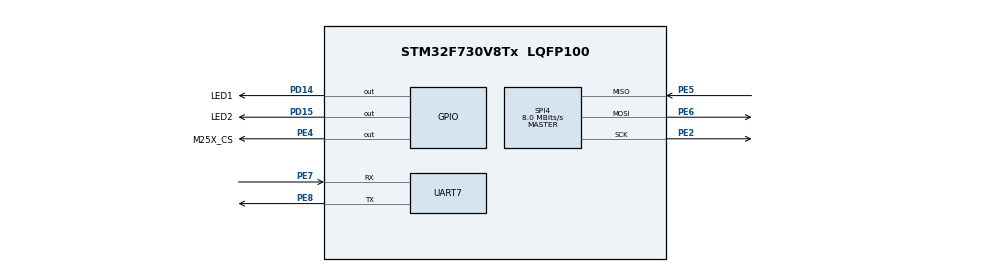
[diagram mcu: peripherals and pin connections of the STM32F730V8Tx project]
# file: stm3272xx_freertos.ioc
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Mcu.Family=STM32F7
PH0-OSC_IN.Signal=RCC_OSC_IN
SPI4.VirtualType=VM_MASTER
FREERTOS.Tasks01=defaultTask,24,128,StartDefaultTask,Default,NULL,Dynamic,NULL,NULL;sys_monitor,24,2048,thread_entry_sys_monitor,Default,NULL,Dynamic,NULL,NULL
PD15.GPIO_Label=LED2
SPI4.DataSize=SPI_DATASIZE_8BIT
SPI4.Direction=SPI_DIRECTION_2LINES
ProjectManager.StackSize=0x400
VP_FREERTOS_VS_CMSIS_V2.Mode=CMSIS_V2
PE8.Mode=Asynchronous
NVIC.SPI4_IRQn=true\:5\:0\:false\:false\:true\:true\:true\:true
SPI4.Mode=SPI_MODE_MASTER
ProjectManager.TargetToolchain=STM32CubeIDE
PE2.Mode=Full_Duplex_Master
PE5.Signal=SPI4_MISO
RCC.USBFreq_Value=96000000
SPI4.CLKPolarity=SPI_POLARITY_LOW
RCC.LSE_VALUE=32768
PH0-OSC_IN.Mode=HSE-External-Clock-Source
RCC.HSE_VALUE=25000000
PD14.PinState=GPIO_PIN_SET
board=custom
RCC.VCOOutputFreq_Value=192000000
PD15.PinState=GPIO_PIN_SET
PE6.Mode=Full_Duplex_Master
PE8.Signal=UART7_TX
PE5.Mode=Full_Duplex_Master
PE4.GPIO_Label=M25X_CS
PH1-OSC_OUT.Signal=RCC_OSC_OUT
PE2.Signal=SPI4_SCK
SPI4.CalculateBaudRate=8.0 MBits/s
PD14.GPIO_Label=LED1
PE6.Signal=SPI4_MOSI
PE4.Signal=GPIO_Output
Mcu.Name=STM32F730V8Tx
PD14.Signal=GPIO_Output
PH1-OSC_OUT.Mode=HSE-External-Clock-Source
Mcu.Package=LQFP100
PE7.Mode=Asynchronous
ProjectManager.HeapSize=0x200
RCC.HSI_VALUE=16000000
SPI4.CLKPhase=SPI_PHASE_1EDGE
NVIC.PriorityGroup=NVIC_PRIORITYGROUP_4
PE4.PinState=GPIO_PIN_SET
PE7.Signal=UART7_RX
PD15.Signal=GPIO_Output
NVIC.UART7_IRQn=true\:5\:0\:false\:false\:true\:true\:true\:true

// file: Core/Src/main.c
/* USER CODE BEGIN Header */
/**
  ******************************************************************************
  * @file           : main.c
  * @brief          : Main program body
  ******************************************************************************
  * @attention
  *
  * <h2><center>&copy; Copyright (c) 2023 STMicroelectronics.
  * All rights reserved.</center></h2>
  *
  * This software component is licensed by ST under BSD 3-Clause license,
  * the "License"; You may not use this file except in compliance with the
  * License. You may obtain a copy of the License at:
  *                        opensource.org/licenses/BSD-3-Clause
  *
  ******************************************************************************
  */
/* USER CODE END Header */
#include "main.h"
#include "cmsis_os.h"

/* USER CODE BEGIN Includes */
#include "app.h"
/* USER CODE END Includes */

SPI_HandleTypeDef hspi4;

UART_HandleTypeDef huart7;

/* Definitions for defaultTask */
osThreadId_t defaultTaskHandle;
const osThreadAttr_t defaultTask_attributes = {
  .name = "defaultTask",
  .stack_size = 128 * 4,
  .priority = (osPriority_t) osPriorityNormal,
};
/* Definitions for sys_monitor */
osThreadId_t sys_monitorHandle;
const osThreadAttr_t sys_monitor_attributes = {
  .name = "sys_monitor",
  .stack_size = 2048 * 4,
  .priority = (osPriority_t) osPriorityNormal,
};

void SystemClock_Config(void);
static void MX_GPIO_Init(void);
static void MX_SPI4_Init(void);
static void MX_UART7_Init(void);
void StartDefaultTask(void *argument);
void thread_entry_sys_monitor(void *argument);

/* USER CODE BEGIN 0 */
#ifdef __GNUC__
  #define PUTCHAR_PROTOTYPE int __io_putchar(int ch)
#else
  #define PUTCHAR_PROTOTYPE int fputc(int ch, FILE *f)
#endif
PUTCHAR_PROTOTYPE
{
    HAL_UART_Transmit(&huart7, (uint8_t *)&ch, 1, 0xFF);
    return ch;
}
/* USER CODE END 0 */

int main(void)
{

  /* MCU Configuration--------------------------------------------------------*/

  /* Reset of all peripherals, Initializes the Flash interface and the Systick. */
  HAL_Init();

  /* Configure the system clock */
  SystemClock_Config();

  /* Initialize all configured peripherals */
  MX_GPIO_Init();
  MX_SPI4_Init();
  MX_UART7_Init();
  /* USER CODE BEGIN 2 */
//   W25QXX_Erase_Chip();
  W25QXX_Init();
  printf("W25QXX Init:%04X\r\n", W25QXX_ReadID());
  /* USER CODE END 2 */

  /* Init scheduler */
  osKernelInitialize();

  /* Create the thread(s) */
  /* creation of defaultTask */
  defaultTaskHandle = osThreadNew(StartDefaultTask, NULL, &defaultTask_attributes);

  /* creation of sys_monitor */
  sys_monitorHandle = osThreadNew(thread_entry_sys_monitor, NULL, &sys_monitor_attributes);

  /* Start scheduler */
  osKernelStart();

  /* We should never get here as control is now taken by the scheduler */
  /* Infinite loop */
  while (1)
  {

  }
}

void SystemClock_Config(void)
{
  RCC_OscInitTypeDef RCC_OscInitStruct = {0};
  RCC_ClkInitTypeDef RCC_ClkInitStruct = {0};
  RCC_PeriphCLKInitTypeDef PeriphClkInitStruct = {0};

  /** Configure the main internal regulator output voltage
  */
  __HAL_RCC_PWR_CLK_ENABLE();
  __HAL_PWR_VOLTAGESCALING_CONFIG(PWR_REGULATOR_VOLTAGE_SCALE3);
  /** Initializes the RCC Oscillators according to the specified parameters
  * in the RCC_OscInitTypeDef structure.
  */
  RCC_OscInitStruct.OscillatorType = RCC_OSCILLATORTYPE_HSI;
  RCC_OscInitStruct.HSIState = RCC_HSI_ON;
  RCC_OscInitStruct.HSICalibrationValue = RCC_HSICALIBRATION_DEFAULT;
  RCC_OscInitStruct.PLL.PLLState = RCC_PLL_NONE;
  if (HAL_RCC_OscConfig(&RCC_OscInitStruct) != HAL_OK)
  {
    Error_Handler();
  }
  /** Initializes the CPU, AHB and APB buses clocks
  */
  RCC_ClkInitStruct.ClockType = RCC_CLOCKTYPE_HCLK|RCC_CLOCKTYPE_SYSCLK
                              |RCC_CLOCKTYPE_PCLK1|RCC_CLOCKTYPE_PCLK2;
  RCC_ClkInitStruct.SYSCLKSource = RCC_SYSCLKSOURCE_HSI;
  RCC_ClkInitStruct.AHBCLKDivider = RCC_SYSCLK_DIV1;
  RCC_ClkInitStruct.APB1CLKDivider = RCC_HCLK_DIV1;
  RCC_ClkInitStruct.APB2CLKDivider = RCC_HCLK_DIV1;

  if (HAL_RCC_ClockConfig(&RCC_ClkInitStruct, FLASH_LATENCY_0) != HAL_OK)
  {
    Error_Handler();
  }
  PeriphClkInitStruct.PeriphClockSelection = RCC_PERIPHCLK_UART7;
  PeriphClkInitStruct.Uart7ClockSelection = RCC_UART7CLKSOURCE_PCLK1;
  if (HAL_RCCEx_PeriphCLKConfig(&PeriphClkInitStruct) != HAL_OK)
  {
    Error_Handler();
  }
}

static void MX_SPI4_Init(void)
{

  /* SPI4 parameter configuration*/
  hspi4.Instance = SPI4;
  hspi4.Init.Mode = SPI_MODE_MASTER;
  hspi4.Init.Direction = SPI_DIRECTION_2LINES;
  hspi4.Init.DataSize = SPI_DATASIZE_8BIT;
  hspi4.Init.CLKPolarity = SPI_POLARITY_LOW;
  hspi4.Init.CLKPhase = SPI_PHASE_1EDGE;
  hspi4.Init.NSS = SPI_NSS_SOFT;
  hspi4.Init.BaudRatePrescaler = SPI_BAUDRATEPRESCALER_2;
  hspi4.Init.FirstBit = SPI_FIRSTBIT_MSB;
  hspi4.Init.TIMode = SPI_TIMODE_DISABLE;
  hspi4.Init.CRCCalculation = SPI_CRCCALCULATION_DISABLE;
  hspi4.Init.CRCPolynomial = 7;
  hspi4.Init.CRCLength = SPI_CRC_LENGTH_DATASIZE;
  hspi4.Init.NSSPMode = SPI_NSS_PULSE_ENABLE;
  if (HAL_SPI_Init(&hspi4) != HAL_OK)
  {
    Error_Handler();
  }

}

static void MX_UART7_Init(void)
{

  huart7.Instance = UART7;
  huart7.Init.BaudRate = 115200;
  huart7.Init.WordLength = UART_WORDLENGTH_8B;
  huart7.Init.StopBits = UART_STOPBITS_1;
  huart7.Init.Parity = UART_PARITY_NONE;
  huart7.Init.Mode = UART_MODE_TX_RX;
  huart7.Init.HwFlowCtl = UART_HWCONTROL_NONE;
  huart7.Init.OverSampling = UART_OVERSAMPLING_16;
  huart7.Init.OneBitSampling = UART_ONE_BIT_SAMPLE_DISABLE;
  huart7.AdvancedInit.AdvFeatureInit = UART_ADVFEATURE_NO_INIT;
  if (HAL_UART_Init(&huart7) != HAL_OK)
  {
    Error_Handler();
  }

}

static void MX_GPIO_Init(void)
{
  GPIO_InitTypeDef GPIO_InitStruct = {0};

  /* GPIO Ports Clock Enable */
  __HAL_RCC_GPIOE_CLK_ENABLE();
  __HAL_RCC_GPIOH_CLK_ENABLE();
  __HAL_RCC_GPIOD_CLK_ENABLE();

  /*Configure GPIO pin Output Level */
  HAL_GPIO_WritePin(M25X_CS_GPIO_Port, M25X_CS_Pin, GPIO_PIN_SET);

  /*Configure GPIO pin Output Level */
  HAL_GPIO_WritePin(GPIOD, LED1_Pin|LED2_Pin, GPIO_PIN_SET);

  /*Configure GPIO pin : M25X_CS_Pin */
  GPIO_InitStruct.Pin = M25X_CS_Pin;
  GPIO_InitStruct.Mode = GPIO_MODE_OUTPUT_PP;
  GPIO_InitStruct.Pull = GPIO_NOPULL;
  GPIO_InitStruct.Speed = GPIO_SPEED_FREQ_LOW;
  HAL_GPIO_Init(M25X_CS_GPIO_Port, &GPIO_InitStruct);

  /*Configure GPIO pins : LED1_Pin LED2_Pin */
  GPIO_InitStruct.Pin = LED1_Pin|LED2_Pin;
  GPIO_InitStruct.Mode = GPIO_MODE_OUTPUT_PP;
  GPIO_InitStruct.Pull = GPIO_NOPULL;
  GPIO_InitStruct.Speed = GPIO_SPEED_FREQ_LOW;
  HAL_GPIO_Init(GPIOD, &GPIO_InitStruct);

}

void StartDefaultTask(void *argument)
{
  for(;;)
  {
    osDelay(1);
  }
}

void thread_entry_sys_monitor(void *argument)
{
  /* USER CODE BEGIN thread_entry_sys_monitor */
  /* Infinite loop */
  for(;;)
  {
    osDelay(1);
    app_loop();
  }
  /* USER CODE END thread_entry_sys_monitor */
}

void Error_Handler(void)
{
  __disable_irq();
  while (1)
  {
  }
}

/************************ (C) COPYRIGHT STMicroelectronics *****END OF FILE****/
